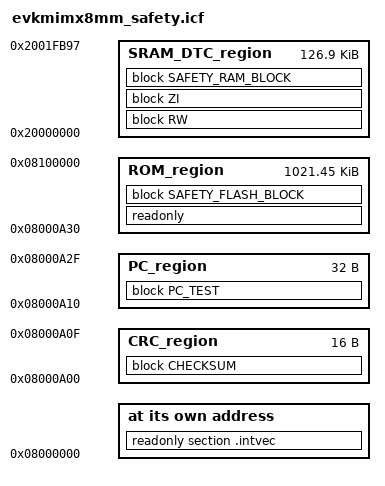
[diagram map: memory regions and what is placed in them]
/*                                     
** ###################################################################
**     Device:              MIMX8MM6
**
**     Compiler:            IAR ANSI C/C++ Compiler for ARM
**
**     Abstract:
**         Linker file for the IAR ANSI C/C++ Compiler for ARM
**
**
**     Copyright 2021 NXP.
**     All rights reserved.
**
**     SPDX-License-Identifier: BSD-3-Clause
**
**
**     http:                 www.nxp.com
**     mail:                 support@nxp.com
**
** ###################################################################
*/

/**********************************************************************************/
/****************************        MEMORY MAP        ****************************/
/**********************************************************************************/
/********************        FLASH        ********************/
//     __________________
//    |                  | --> m_boot_hdr_conf_start
//    |  XIP boot header |
//    |__________________|
//    |                  | --> ROM_interrupts_start
//    |       IVT        |
//    |__________________|
//    |                  | --> __FlashCRC_start__
//    |       CRC        |
//    |__________________|
//    |                  | --> __PC_test_start__
//    |   PC_object.o    |
//    |__________________|
//    |                  | --> ROM_start
//    |     readonly     |
//    |   .textrw_init   |
//    |   .data_init     |
//    |__________________| --> ROM_end
//
//
/********************        SRAM        ********************/
//     __________________
//    |                  | --> SRAM_ITC_start
//    |//// NOT USED ////|
//    |__________________| --> SRAM_ITC_end 
//    |                  |
//    |//// RESERVED ////|
//    |__________________|
//    |                  | --> SRAM_DTC_start
//    |     RW (.data)   | --> copying in startup_iar.c
//    |     ZI (.bss)    | --> copying in startup_iar.c
//    | SAFETY_RAM_BLOCK | 
//    |__________________| --> SRAM_DTC_end_edited
//    |                  | --> m_stack_test_p_1
//    |                  |
//    |__________________| --> m_stack_test_p_2
//    |                  |
//    |                  |
//    |      STACK       |
//    |                  |
//    |__________________| --> __BOOT_STACK_ADDRESS
//    |                  | --> m_stack_test_p_3
//    |                  |
//    |__________________| --> m_stack_test_p_4
//    |__________________| --> m_safety_error_code
//    |__________________| --> m_pc_test_flag
//    |                  | --> m_wd_test_backup
//    |__________________|
//    |                  |
//    |                  | --> m_ram_test_backup
//    |__________________|
//    |__________________| --> SRAM_DTC_end
//    |                  |
//    |//// RESERVED ////|
//    |__________________|
//    |                  | --> SRAM_OC_start
//    |//// NOT USED ////|
//    |__________________| --> SRAM_OC_end
//
//
/********************        SDRAM        ********************/
//     __________________
//    |                  | --> SDRAM_start
//    |//// NOT USED ////|
//    |__________________| --> SDRAM_end
//

/******************************************************************************/
/******************     USER CONFIGURATION PART     ***************************/
/******************************************************************************/
define exported symbol stack_test_block_size = 0x10;
define exported symbol ram_test_backup_size  = 0x20;
define symbol __vector_table_size__          = 0xA00;
define symbol __size_cstack__                = 0x0400;

define symbol SRAM_DTC_start       = 0x20000000; /* Part of on-chip RAM */
define symbol SRAM_DTC_end         = 0x2001FFFF;

define symbol ROM_interrupts_start = 0x08000000; /* IVT in ROM */
define symbol ROM_interrupts_end   = ROM_interrupts_start + __vector_table_size__ - 1;

define symbol __FlashCRC_start__   = 0x08000A00; /* Place checksum result after IVT (in ROM) */
define symbol __FlashCRC_end__     = 0x08000A0F;

define symbol __PC_test_start__    = 0x08000A10; /* PC object address */
define symbol __PC_test_end__      = 0x08000A2F; /* PC object reserved size: 0x20 */ 

define symbol ROM_start            = 0x08000A30; /* ROM memory (external ROM) */
define symbol ROM_end              = 0x08100000;

define exported symbol __VECTOR_TABLE = ROM_interrupts_start;

/* UNUSED - only for SDK compatibility */
define exported symbol __CACHE_REGION_START = ROM_interrupts_start;
define exported symbol __CACHE_REGION_SIZE  = 0x0;

/******************************************************************************/
/******************     SYMBOLS     *******************************************/
/******************************************************************************/ 
define exported symbol m_ram_test_backup    = SRAM_DTC_end - ram_test_backup_size + 0x1;
define exported symbol m_wd_test_backup     = m_ram_test_backup - 0x20;
define exported symbol m_pc_test_flag       = m_wd_test_backup - 0x4;
define exported symbol m_safety_error_code  = m_pc_test_flag - 0x4;
define exported symbol m_stack_test_p_4     = m_safety_error_code - 0x4;
define exported symbol m_stack_test_p_3     = m_stack_test_p_4 - stack_test_block_size +0x4;
define exported symbol __BOOT_STACK_ADDRESS = m_stack_test_p_3 - 0x4;
define exported symbol m_stack_test_p_2     = __BOOT_STACK_ADDRESS - __size_cstack__;
define exported symbol m_stack_test_p_1     = m_stack_test_p_2 - stack_test_block_size + 0x4;
define symbol SRAM_DTC_end_edited           = m_stack_test_p_1 - 0x1;

/******************************************************************************/
/******************     REGIONS     *******************************************/
/******************************************************************************/
define memory mem with size   = 4G;
define region CRC_region      = mem:[from __FlashCRC_start__  to __FlashCRC_end__];
define region PC_region       = mem:[from __PC_test_start__ to __PC_test_end__];
define region ROM_region      = mem:[from ROM_start to ROM_end];
define region SRAM_DTC_region = mem:[from SRAM_DTC_start to SRAM_DTC_end_edited];

/******************************************************************************/
/******************     SECTIONS & BLOCKS    **********************************/
/******************************************************************************/
initialize manually           { readwrite };
initialize manually           { section .data };
initialize manually           { section .bss };
initialize manually           { section .textrw };
initialize manually           { section .safety_ram };
do not initialize             { section .noinit };

define block RW               { readwrite };
define block ZI               { zi };
define block PC_TEST          { section .text object iec60730b_cm4_cm7_pc_object.o };
define block CHECKSUM         { section .checksum };
define block SAFETY_RAM_BLOCK { section .safety_ram };
define block SAFETY_FLASH_BLOCK with fixed order
{
 readonly section checksum_start_mark,
 section .text         object  main_imx8m.o,
 section .text         object  safety_cm4_cm7_imx8m.o,
 section .rodata       object  safety_cm4_cm7_imx8m.o,
 readonly section checksum_end_mark
};

/*****************************************************/
/******************     PLACING     ******************/
/*****************************************************/

place at address mem:ROM_interrupts_start { readonly section .intvec };

place in ROM_region      { readonly };
place in ROM_region      { block SAFETY_FLASH_BLOCK};
place in CRC_region      { block CHECKSUM };
place in PC_region       { block PC_TEST};
place in SRAM_DTC_region { block RW, block ZI };
place in SRAM_DTC_region { block SAFETY_RAM_BLOCK };
